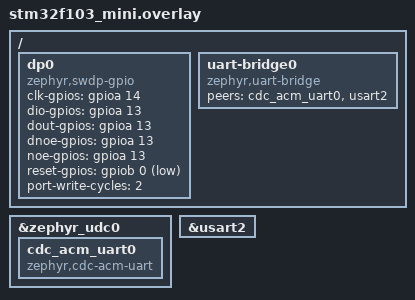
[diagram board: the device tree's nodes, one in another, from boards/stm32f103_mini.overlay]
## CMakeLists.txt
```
# Copyright (c) 2024 Kabirz
# SPDX-License-Identifier: Apache-2.0

cmake_minimum_required(VERSION 3.20.0)

find_package(Zephyr REQUIRED HINTS $ENV{ZEPHYR_BASE})
project(zephyrLink)

target_sources(app PRIVATE src/main.c)
```

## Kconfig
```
# Copyright (c) 2024 Kabirz
# SPDX-License-Identifier: Apache-2.0

source "Kconfig.zephyr"
```

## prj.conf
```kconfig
# Copyright (c) 2024 Kabirz
# SPDX-License-Identifier: Apache-2.0

# USB device stack (new experimental stack)
CONFIG_USB_DEVICE_STACK_NEXT=y
CONFIG_UDC_DRIVER=y

# WebUSB support: BOS descriptor + vendor request handler
CONFIG_USBD_BOS_SUPPORT=y
CONFIG_USBD_VREQ_SUPPORT=y

# Zephyr built-in CMSIS-DAP subsystem
CONFIG_DAP=y
CONFIG_DAP_BACKEND_USB=y

# CDC ACM (serial bridge)
CONFIG_USBD_CDC_ACM_CLASS=y
CONFIG_CDC_ACM_SERIAL_INITIALIZE_AT_BOOT=n
CONFIG_UART_LINE_CTRL=y
CONFIG_UART_USE_RUNTIME_CONFIGURE=y

# UART bridge (CDC ACM <-> target USART)
CONFIG_UART_BRIDGE=y

# Basic drivers
CONFIG_GPIO=y
CONFIG_SERIAL=y

# Memory optimization (48KB RAM on STM32F103RCT6)
CONFIG_MAIN_STACK_SIZE=1024
CONFIG_HEAP_MEM_POOL_SIZE=256

# Logging
CONFIG_LOG=y
CONFIG_LOG_DEFAULT_LEVEL=3
CONFIG_DAP_LOG_LEVEL_INF=y
```

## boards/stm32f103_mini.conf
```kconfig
# Copyright (c) 2024 Kabirz
# SPDX-License-Identifier: Apache-2.0

# USB device stack (new experimental stack)
CONFIG_USB_DEVICE_STACK_NEXT=y
CONFIG_UDC_DRIVER=y

# Zephyr built-in CMSIS-DAP subsystem
CONFIG_DAP=y
CONFIG_DAP_BACKEND_USB=y

# CDC ACM (serial bridge)
CONFIG_USBD_CDC_ACM_CLASS=y
CONFIG_CDC_ACM_SERIAL_INITIALIZE_AT_BOOT=n
CONFIG_UART_LINE_CTRL=y
CONFIG_UART_USE_RUNTIME_CONFIGURE=y

# UART bridge (CDC ACM <-> target USART)
CONFIG_UART_BRIDGE=y

# Basic drivers
CONFIG_GPIO=y
CONFIG_SERIAL=y

# Memory optimization (48KB RAM on STM32F103RCT6)
CONFIG_MAIN_STACK_SIZE=1024
CONFIG_HEAP_MEM_POOL_SIZE=256

# Logging
CONFIG_LOG=y
CONFIG_LOG_DEFAULT_LEVEL=3
```

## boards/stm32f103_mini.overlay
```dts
/*
 * Copyright (c) 2024 Kabirz
 *
 * SPDX-License-Identifier: Apache-2.0
 *
 * ZephyrLink - CMSIS-DAP Debug Probe Overlay for STM32F103RCT6 Mini Board
 *
 * Adds:
 *   - SWD bit-bang GPIO (zephyr,swdp-gpio)
 *   - CDC ACM UART instance
 *   - UART bridge (CDC ACM <-> USART2)
 */

/ {
	/* SWD bit-bang GPIO for CMSIS-DAP debug port */
	dp0 {
		compatible = "zephyr,swdp-gpio";
		status = "okay";

		clk-gpios = <&gpioa 14 GPIO_ACTIVE_HIGH>;
		dio-gpios = <&gpioa 13 GPIO_PULL_UP>;
		dout-gpios = <&gpioa 13 GPIO_ACTIVE_HIGH>;
		dnoe-gpios = <&gpioa 13 GPIO_ACTIVE_HIGH>;
		noe-gpios = <&gpioa 13 GPIO_ACTIVE_HIGH>;
		reset-gpios = <&gpiob 0 GPIO_ACTIVE_LOW>;
		port-write-cycles = <2>;
	};

	/* UART bridge: CDC ACM <-> USART2 (PA2/PA3) */
	uart-bridge0 {
		compatible = "zephyr,uart-bridge";
		peers = <&cdc_acm_uart0 &usart2>;
	};
};

/* CDC ACM UART instance (child of USB controller) */
&zephyr_udc0 {
	cdc_acm_uart0: cdc_acm_uart0 {
		compatible = "zephyr,cdc-acm-uart";
	};
};

/* Enable USART2 for UART bridge (PA2/PA3 already configured in base DTS) */
&usart2 {
	status = "okay";
};
```

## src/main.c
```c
/*
 * Copyright (c) 2024 Kabirz
 *
 * SPDX-License-Identifier: Apache-2.0
 *
 * ZephyrLink - CMSIS-DAP Debug Probe
 *
 * Turns an STM32F103RCT6 (stm32f103_mini) board into a CMSIS-DAP v2
 * debug probe with CDC ACM serial bridge.
 *
 * Uses Zephyr built-in DAP subsystem (CONFIG_DAP + CONFIG_DAP_BACKEND_USB)
 * with the new USB device stack (CONFIG_USB_DEVICE_STACK_NEXT).
 */

#include <zephyr/kernel.h>
#include <zephyr/usb/usbd.h>
#include <zephyr/dap/dap_link.h>

#include <zephyr/logging/log.h>
LOG_MODULE_REGISTER(zephyr_link, LOG_LEVEL_INF);

#include "webusb.h"
#include "msosv2.h"

/* DAP Link context bound to the zephyr,swdp-gpio instance (dp0) */
DAP_LINK_CONTEXT_DEFINE(zl_dap_ctx, DEVICE_DT_GET_ONE(zephyr_swdp_gpio));

/* USB device context */
USBD_DEVICE_DEFINE(zl_usbd,
		   DEVICE_DT_GET(DT_NODELABEL(zephyr_udc0)),
		   0x0D28,  /* ARM Ltd. VID */
		   0x0204); /* CMSIS-DAP PID */

/* String descriptors */
USBD_DESC_LANG_DEFINE(zl_lang);
USBD_DESC_MANUFACTURER_DEFINE(zl_mfr, "ZephyrLink");
USBD_DESC_PRODUCT_DEFINE(zl_product, "CMSIS-DAP Probe");
USBD_DESC_SERIAL_NUMBER_DEFINE(zl_sn);

/* Full-Speed configuration */
USBD_DESC_CONFIG_DEFINE(zl_fs_cfg_desc, "ZephyrLink FS");
USBD_CONFIGURATION_DEFINE(zl_fs_config,
			  USB_SCD_SELF_POWERED,
			  125, /* 250 mA */
			  &zl_fs_cfg_desc);

int main(void)
{
	int ret;

	/* Initialize DAP Link (SWD bit-bang) */
	ret = dap_link_init(&zl_dap_ctx);
	if (ret) {
		LOG_ERR("DAP Link init failed: %d", ret);
		return ret;
	}
	LOG_INF("DAP Link initialized");

	/* Initialize DAP USB backend (binds context to USB class) */
	ret = dap_link_backend_usb_init(&zl_dap_ctx);
	if (ret) {
		LOG_ERR("DAP USB backend init failed: %d", ret);
		return ret;
	}
	LOG_INF("DAP USB backend initialized");

	/* Set up USB device descriptors */
	ret = usbd_add_descriptor(&zl_usbd, &zl_lang);
	if (ret) {
		LOG_ERR("Failed to add language descriptor: %d", ret);
		return ret;
	}

	ret = usbd_add_descriptor(&zl_usbd, &zl_mfr);
	if (ret) {
		LOG_ERR("Failed to add manufacturer descriptor: %d", ret);
		return ret;
	}

	ret = usbd_add_descriptor(&zl_usbd, &zl_product);
	if (ret) {
		LOG_ERR("Failed to add product descriptor: %d", ret);
		return ret;
	}

	ret = usbd_add_descriptor(&zl_usbd, &zl_sn);
	if (ret) {
		LOG_ERR("Failed to add serial number descriptor: %d", ret);
		return ret;
	}

	/* Add Full-Speed configuration */
	ret = usbd_add_configuration(&zl_usbd, USBD_SPEED_FS, &zl_fs_config);
	if (ret) {
		LOG_ERR("Failed to add FS configuration: %d", ret);
		return ret;
	}

	/* WebUSB requires bcdUSB >= 2.1. The default bcdUSB set by
	 * USBD_DEVICE_DEFINE is 2.0 — bump it here.
	 */
	ret = usbd_device_set_bcd_usb(&zl_usbd, USBD_SPEED_FS, USB_SRN_2_1);
	if (ret) {
		LOG_ERR("Failed to set bcdUSB to 2.1: %d", ret);
		return ret;
	}

	/* Add WebUSB Platform Capability to BOS (required by Chrome/Edge) */
	ret = usbd_add_descriptor(&zl_usbd, &bos_vreq_webusb);
	if (ret) {
		LOG_ERR("Failed to add WebUSB BOS capability: %d", ret);
		return ret;
	}

	/* Add MS OS 2.0 BOS capability (required for Windows WebUSB access) */
	ret = usbd_add_descriptor(&zl_usbd, &bos_vreq_msosv2);
	if (ret) {
		LOG_ERR("Failed to add MS OS 2.0 BOS capability: %d", ret);
		return ret;
	}

	/* Register all USB classes (DAP bulk + CDC ACM) */
	ret = usbd_register_all_classes(&zl_usbd, USBD_SPEED_FS, 1, NULL);
	if (ret) {
		LOG_ERR("Failed to register USB classes: %d", ret);
		return ret;
	}

	/* Set composite device class code (IAD) */
	usbd_device_set_code_triple(&zl_usbd, USBD_SPEED_FS,
				    USB_BCC_MISCELLANEOUS, 0x02, 0x01);

	usbd_self_powered(&zl_usbd, true);

	/* Initialize USB device */
	ret = usbd_init(&zl_usbd);
	if (ret) {
		LOG_ERR("Failed to init USB device: %d", ret);
		return ret;
	}

	/* Enable USB (required for devices without VBUS detection, e.g. STM32F1) */
	ret = usbd_enable(&zl_usbd);
	if (ret) {
		LOG_ERR("Failed to enable USB device: %d", ret);
		return ret;
	}

	LOG_INF("ZephyrLink CMSIS-DAP ready (VID=0x0D28 PID=0x0204)");
	return 0;
}
```

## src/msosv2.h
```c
/*
 * MS OS 2.0 Descriptor for ZephyrLink
 *
 * Required on Windows so the OS auto-loads WinUSB.sys for our device.
 * Without it, Chrome/Edge on Windows cannot claim the WebUSB interface
 * and requestDevice() will fail with "Access denied".
 *
 * Reference: https://learn.microsoft.com/en-us/windows-hardware/drivers/usbcon/
 *            microsoft-os-2-0-descriptors-specification
 * Adapted from zephyr/samples/subsys/dap/src/msosv2.h
 */

#ifndef ZEPHYRLINK_MSOSV2_H
#define ZEPHYRLINK_MSOSV2_H

#include <zephyr/kernel.h>
#include <zephyr/sys/byteorder.h>
#include <zephyr/usb/usbd.h>
#include <zephyr/usb/msos_desc.h>
#include <zephyr/net_buf.h>
#include <zephyr/logging/log.h>

/* Vendor request code for MS OS 2.0 descriptor requests
 * Must be unique across all vendor request codes on this device.
 * WebUSB uses 0x01, so MSOS 2.0 uses 0x02.
 */
#define ZEPHYRLINK_MSOS2_VENDOR_CODE  0x02U

/* Windows version (Windows 10) reported in dwWindowsVersion */
#define ZEPHYRLINK_MSOS2_OS_VERSION   0x0A000000UL

/* DeviceInterfaceGUID: {3367AA52-11A8-4FA6-A783-192849063453}
 * The sample uses a CMSIS-DAP specific GUID; we use a ZephyrLink GUID.
 * UTF-16LE encoded (without BOM).
 */
#define ZEPHYRLINK_DEVICE_INTERFACE_GUIDS_PROPERTY               \
	'D', 0x00, 'e', 0x00, 'v', 0x00, 'i', 0x00,              \
	'c', 0x00, 'e', 0x00, 'I', 0x00, 'n', 0x00,              \
	't', 0x00, 'e', 0x00, 'r', 0x00, 'f', 0x00,              \
	'a', 0x00, 'c', 0x00, 'e', 0x00, 'G', 0x00,              \
	'U', 0x00, 'I', 0x00, 'D', 0x00, 's', 0x00,              \
	0x00, 0x00

#define ZEPHYRLINK_DEVICE_INTERFACE_GUID_DATA                   \
	'{', 0x00, '3', 0x00, '3', 0x00, '6', 0x00,              \
	'7', 0x00, 'A', 0x00, 'A', 0x00, '5', 0x00,              \
	'2', 0x00, '-', 0x00, '1', 0x00, '1', 0x00,              \
	'A', 0x00, '8', 0x00, '-', 0x00, '4', 0x00,              \
	'F', 0x00, 'A', 0x00, '6', 0x00, '-', 0x00,              \
	'A', 0x00, '7', 0x00, '8', 0x00, '3', 0x00,              \
	'-', 0x00, '1', 0x00, '9', 0x00, '2', 0x00,              \
	'8', 0x00, '4', 0x00, '9', 0x00, '0', 0x00,              \
	'6', 0x00, '3', 0x00, '4', 0x00, '5', 0x00,              \
	'3', 0x00, '}', 0x00, 0x00, 0x00

struct msosv2_descriptor {
	struct msosv2_descriptor_set_header header;
#if defined(CONFIG_USBD_CDC_ACM_CLASS)
	struct msosv2_function_subset_header subset_header;
#endif
	struct msosv2_compatible_id compatible_id;
	struct msosv2_guids_property guids_property;
} __packed;

static struct msosv2_descriptor msosv2_desc = {
	.header = {
		.wLength          = sizeof(struct msosv2_descriptor_set_header),
		.wDescriptorType  = MS_OS_20_SET_HEADER_DESCRIPTOR,
		.dwWindowsVersion = sys_cpu_to_le32(ZEPHYRLINK_MSOS2_OS_VERSION),
		.wTotalLength     = sizeof(msosv2_desc),
	},
#if defined(CONFIG_USBD_CDC_ACM_CLASS)
	.subset_header = {
		.wLength         = sizeof(struct msosv2_function_subset_header),
		.wDescriptorType = MS_OS_20_SUBSET_HEADER_FUNCTION,
		.bFirstInterface = 0,
		.wSubsetLength   = sizeof(struct msosv2_compatible_id)
				 + sizeof(struct msosv2_guids_property),
	},
#endif
	.compatible_id = {
		.wLength         = sizeof(struct msosv2_compatible_id),
		.wDescriptorType = MS_OS_20_FEATURE_COMPATIBLE_ID,
		.CompatibleID    = { 'W', 'I', 'N', 'U', 'S', 'B', 0x00, 0x00 },
	},
	.guids_property = {
		.wLength             = sizeof(struct msosv2_guids_property),
		.wDescriptorType     = MS_OS_20_FEATURE_REG_PROPERTY,
		.wPropertyDataType   = MS_OS_20_PROPERTY_DATA_REG_SZ,
		.wPropertyNameLength = sizeof(struct msosv2_guids_property) -
				       offsetof(struct msosv2_guids_property, PropertyName),
		.PropertyName        = ZEPHYRLINK_DEVICE_INTERFACE_GUIDS_PROPERTY,
		.wPropertyDataLength = sizeof(struct msosv2_guids_property) -
				       offsetof(struct msosv2_guids_property, bPropertyData),
		.bPropertyData       = ZEPHYRLINK_DEVICE_INTERFACE_GUID_DATA,
	},
};

/* MS OS 2.0 vendor request callback
 * Windows issues GET_DESCRIPTOR (wIndex=0x07) for MSOS 2.0 right after
 * enumeration. We return the full descriptor set in a single transfer.
 */
static int msosv2_to_host_cb(const struct usbd_context *const ctx,
			     const struct usb_setup_packet *const setup,
			     struct net_buf *const buf)
{
	if (setup->wIndex == MS_OS_20_DESCRIPTOR_INDEX) {
		LOG_INF("MS OS 2.0: GET_DESCRIPTOR");
		net_buf_add_mem(buf, &msosv2_desc,
				MIN(net_buf_tailroom(buf), sizeof(msosv2_desc)));
		return 0;
	}
	return -ENOTSUP;
}

static int msosv2_to_dev_cb(const struct usbd_context *const ctx,
			    const struct usb_setup_packet *const setup,
			    const struct net_buf *const buf)
{
	ARG_UNUSED(ctx);
	ARG_UNUSED(setup);
	ARG_UNUSED(buf);
	return -ENOTSUP;
}

USBD_DESC_BOS_VREQ_DEFINE(bos_vreq_msosv2,
			  sizeof(msosv2_desc),
			  &msosv2_desc,
			  ZEPHYRLINK_MSOS2_VENDOR_CODE,
			  msosv2_to_host_cb,
			  msosv2_to_dev_cb);

#endif /* ZEPHYRLINK_MSOSV2_H */
```

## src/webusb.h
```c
/*
 * WebUSB support for ZephyrLink
 *
 * Defines:
 *   - WebUSB Platform Capability Descriptor (added to BOS)
 *   - WebUSB URL Descriptor (landing page for browsers)
 *   - Vendor request callback that handles GET_URL
 *
 * Reference: https://wicg.github.io/webusb/
 * Adapted from zephyr/samples/subsys/dap/src/webusb.h
 */

#ifndef ZEPHYRLINK_WEBUSB_H
#define ZEPHYRLINK_WEBUSB_H

#include <zephyr/kernel.h>
#include <zephyr/sys/byteorder.h>
#include <zephyr/sys/min_heap.h>
#include <zephyr/usb/usbd.h>
#include <zephyr/usb/bos.h>
#include <zephyr/net_buf.h>
#include <zephyr/logging/log.h>

/* WebUSB protocol constants */
#define WEBUSB_REQ_GET_URL             0x02U
#define WEBUSB_DESC_TYPE_URL           0x03U
#define WEBUSB_URL_PREFIX_HTTP         0x00U
#define WEBUSB_URL_PREFIX_HTTPS        0x01U

/* Vendor request code and landing page index
 * Must be unique among all vendor request codes registered on this device.
 */
#define ZEPHYRLINK_WEBUSB_VENDOR_CODE  0x01U
#define ZEPHYRLINK_WEBUSB_LANDING_PAGE 0x01U

/* Combined descriptor: platform + webusb cap
 * The usbd stack concatenates these into a single BOS capability entry.
 */
struct usb_bos_webusb_desc {
	struct usb_bos_platform_descriptor platform;
	struct usb_bos_capability_webusb  cap;
} __packed;

static const struct usb_bos_webusb_desc bos_cap_webusb = {
	/* WebUSB Platform Capability Descriptor
	 * https://wicg.github.io/webusb/#webusb-platform-capability-descriptor
	 */
	.platform = {
		.bLength = sizeof(struct usb_bos_platform_descriptor)
			 + sizeof(struct usb_bos_capability_webusb),
		.bDescriptorType     = USB_DESC_DEVICE_CAPABILITY,
		.bDevCapabilityType  = USB_BOS_CAPABILITY_PLATFORM,
		.bReserved           = 0,
		/* WebUSB UUID: 3408b638-09a9-47a0-8bfd-a0768815b665
		 * (little-endian on the wire)
		 */
		.PlatformCapabilityUUID = {
			0x38, 0xB6, 0x08, 0x34,
			0xA9, 0x09,
			0xA0, 0x47,
			0x8B, 0xFD,
			0xA0, 0x76, 0x88, 0x15, 0xB6, 0x65,
		},
	},
	.cap = {
		.bcdVersion   = sys_cpu_to_le16(0x0100),
		.bVendorCode  = ZEPHYRLINK_WEBUSB_VENDOR_CODE,
		.iLandingPage = ZEPHYRLINK_WEBUSB_LANDING_PAGE,
	}
};

/* WebUSB URL Descriptor
 * When the user plugs the device in, Chrome/Edge fetches this URL and
 * uses it for origin validation. The origin (scheme + host + port) of
 * this URL must match the origin of any page that calls
 * navigator.usb.requestDevice() and wants to access this device.
 *
 * Currently pointing at the official mbed dapjs example page on GitHub
 * Pages, so the device can be used directly with dapjs's WebUSB demos:
 *   https://armmbed.github.io/dapjs/examples/index.html
 *
 * Format: bLength | bDescriptorType | bScheme | UTF-8 URL (no scheme prefix)
 */
static const uint8_t webusb_origin_url[] = {
	0x2E,                                    /* bLength = 46 bytes (3 + 43) */
	WEBUSB_DESC_TYPE_URL,                    /* bDescriptorType = URL */
	WEBUSB_URL_PREFIX_HTTPS,                 /* bScheme = https */
	'a', 'r', 'm', 'm', 'b', 'e', 'd', '.', 'g', 'i', 't', 'h', 'u', 'b', '.', 'i', 'o',
	'/', 'd', 'a', 'p', 'j', 's', '/', 'e', 'x', 'a', 'm', 'p', 'l', 'e', 's',
	'/', 'i', 'n', 'd', 'e', 'x', '.', 'h', 't', 'm', 'l',
};

/* GET_URL vendor request handler
 *
 * Invoked by the usbd stack when the host issues a control transfer
 * with bmRequestType = Device-to-Host, bRequest = bVendorCode, wIndex = 0x02.
 * We return the URL descriptor for the requested landing page index.
 */
static int webusb_to_host_cb(const struct usbd_context *const ctx,
			     const struct usb_setup_packet *const setup,
			     struct net_buf *const buf)
{
	if (setup->wIndex == WEBUSB_REQ_GET_URL) {
		uint8_t index = USB_GET_DESCRIPTOR_INDEX(setup->wValue);

		if (index != ZEPHYRLINK_WEBUSB_LANDING_PAGE) {
			return -ENOTSUP;
		}

		net_buf_add_mem(buf, &webusb_origin_url,
				MIN(net_buf_tailroom(buf), sizeof(webusb_origin_url)));

		LOG_INF("WebUSB: GET_URL index=%u", index);
		return 0;
	}

	return -ENOTSUP;
}

/* Single-shot no-op for host-to-device direction (not used by WebUSB). */
static int webusb_to_dev_cb(const struct usbd_context *const ctx,
			    const struct usb_setup_packet *const setup,
			    const struct net_buf *const buf)
{
	ARG_UNUSED(ctx);
	ARG_UNUSED(setup);
	ARG_UNUSED(buf);
	return -ENOTSUP;
}

/* Register the WebUSB BOS capability + its vendor request handler */
USBD_DESC_BOS_VREQ_DEFINE(bos_vreq_webusb,
			  sizeof(bos_cap_webusb),
			  &bos_cap_webusb,
			  ZEPHYRLINK_WEBUSB_VENDOR_CODE,
			  webusb_to_host_cb,
			  webusb_to_dev_cb);

#endif /* ZEPHYRLINK_WEBUSB_H */
```
